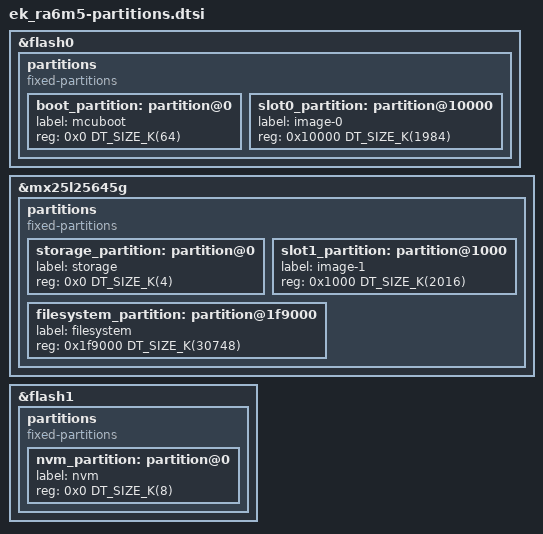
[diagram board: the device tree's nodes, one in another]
/* Partition layout for ek_ra6m5: the flash memory map shared by the
 * bootloader and every application image. Generated by
 * tools/partition_layout.py; do not edit by hand -- re-run
 * `python3 tools/partition_layout.py --fix ek_ra6m5` after changing
 * the upstream board geometry or tools/boards.toml.
 *
 * Board-specific overlay glue (delete-nodes, device enablement,
 * aliases/chosen) lives in dts/renesas/ek_ra6m5.dtsi, which includes
 * this file.
 */

&flash0 {
	partitions {
		compatible = "fixed-partitions";
		#address-cells = <1>;
		#size-cells = <1>;

		boot_partition: partition@0 {
			label = "mcuboot";
			reg = <0x0 DT_SIZE_K(64)>;
		};

		slot0_partition: partition@10000 {
			label = "image-0";
			reg = <0x10000 DT_SIZE_K(1984)>;
		};
	};
};

&mx25l25645g {
	partitions {
		compatible = "fixed-partitions";
		#address-cells = <1>;
		#size-cells = <1>;

		storage_partition: partition@0 {
			label = "storage";
			reg = <0x0 DT_SIZE_K(4)>;
		};

		slot1_partition: partition@1000 {
			label = "image-1";
			reg = <0x1000 DT_SIZE_K(2016)>;
		};

		filesystem_partition: partition@1f9000 {
			label = "filesystem";
			reg = <0x1f9000 DT_SIZE_K(30748)>;
		};
	};
};

&flash1 {
	partitions {
		compatible = "fixed-partitions";
		#address-cells = <1>;
		#size-cells = <1>;

		nvm_partition: partition@0 {
			label = "nvm";
			reg = <0x0 DT_SIZE_K(8)>;
		};
	};
};
